# CONTROL_MODULE register map
Vendor: Texas Instruments
Registers are 32-bit, access per field, no defined reset value unless marked. A register's access mark holds for its fields unless they carry their own. Offsets are as the file gives them; [hi:lo] are bit positions; {n}, {i} and the like mark numbered series.

## CONTROL_MODULE (part 5 of 5)
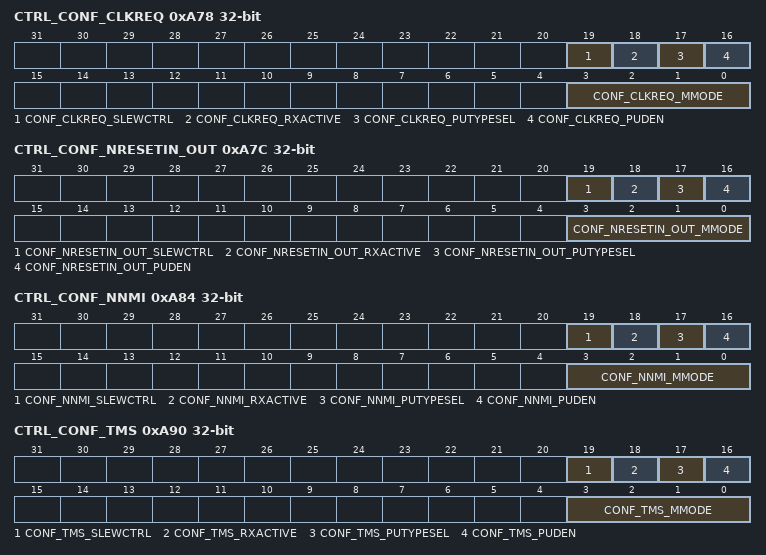
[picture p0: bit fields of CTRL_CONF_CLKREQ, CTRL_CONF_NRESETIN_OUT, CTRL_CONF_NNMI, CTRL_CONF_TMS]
0xA78 CTRL_CONF_CLKREQ
  [19] CONF_CLKREQ_SLEWCTRL rw — Select between Faster or Slower Slew rate [[br]]0 = fast [[br]]1 = slow
  [18] CONF_CLKREQ_RXACTIVE rw — Input Enable Value for the PAD [[br]]0 = receiver disabled [[br]]1 = receiver enabled
  [17] CONF_CLKREQ_PUTYPESEL rw — Pad Pullup / Pulldown Type Selection [[br]]0 = Pulldown selected [[br]]1 = Pullup selected
  [16] CONF_CLKREQ_PUDEN rw — Pad Pullup / Pulldown Enable. [[br]]This is an active low signal [[br]]1 = Pullup / Pulldown disabled [[br]]0 = Pullup / Pulldown enabled
  [3:0] CONF_CLKREQ_MMODE rw — Pad Functional Signal Mux Select
0xA7C CTRL_CONF_NRESETIN_OUT
  [19] CONF_NRESETIN_OUT_SLEWCTRL rw — Select between Faster or Slower Slew rate [[br]]0 = fast [[br]]1 = slow
  [18] CONF_NRESETIN_OUT_RXACTIVE rw — Input Enable Value for the PAD [[br]]0 = receiver disabled [[br]]1 = receiver enabled
  [17] CONF_NRESETIN_OUT_PUTYPESEL rw — Pad Pullup / Pulldown Type Selection [[br]]0 = Pulldown selected [[br]]1 = Pullup selected
  [16] CONF_NRESETIN_OUT_PUDEN rw — Pad Pullup / Pulldown Enable. [[br]]This is an active low signal [[br]]1 = Pullup / Pulldown disabled [[br]]0 = Pullup / Pulldown enabled
  [3:0] CONF_NRESETIN_OUT_MMODE rw — Pad Functional Signal Mux Select
0xA84 CTRL_CONF_NNMI
  [19] CONF_NNMI_SLEWCTRL rw — Select between Faster or Slower Slew rate [[br]]0 = fast [[br]]1 = slow
  [18] CONF_NNMI_RXACTIVE rw — Input Enable Value for the PAD [[br]]0 = receiver disabled [[br]]1 = receiver enabled
  [17] CONF_NNMI_PUTYPESEL rw — Pad Pullup / Pulldown Type Selection [[br]]0 = Pulldown selected [[br]]1 = Pullup selected
  [16] CONF_NNMI_PUDEN rw — Pad Pullup / Pulldown Enable. [[br]]This is an active low signal [[br]]1 = Pullup / Pulldown disabled [[br]]0 = Pullup / Pulldown enabled
  [3:0] CONF_NNMI_MMODE rw — Pad Functional Signal Mux Select
0xA90 CTRL_CONF_TMS
  [19] CONF_TMS_SLEWCTRL rw — Select between Faster or Slower Slew rate [[br]]0 = fast [[br]]1 = slow
  [18] CONF_TMS_RXACTIVE rw — Input Enable Value for the PAD [[br]]0 = receiver disabled [[br]]1 = receiver enabled
  [17] CONF_TMS_PUTYPESEL rw — Pad Pullup / Pulldown Type Selection [[br]]0 = Pulldown selected [[br]]1 = Pullup selected
  [16] CONF_TMS_PUDEN rw — Pad Pullup / Pulldown Enable. [[br]]This is an active low signal [[br]]1 = Pullup / Pulldown disabled [[br]]0 = Pullup / Pulldown enabled
  [3:0] CONF_TMS_MMODE rw — Pad Functional Signal Mux Select
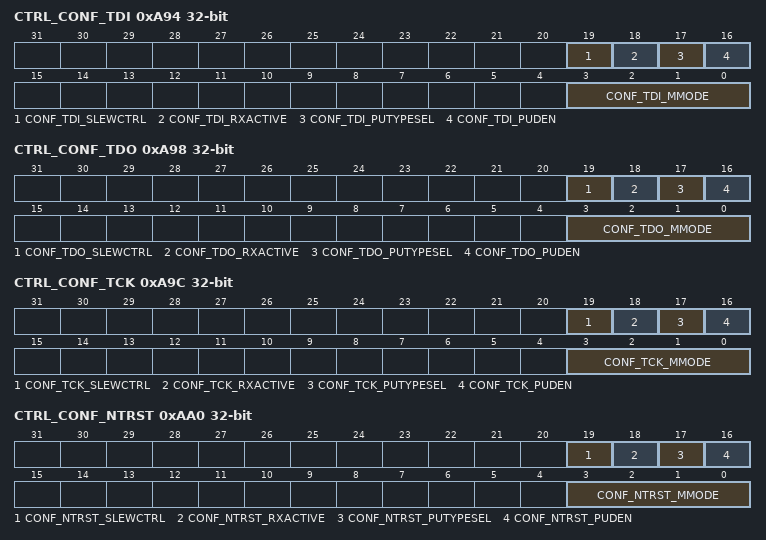
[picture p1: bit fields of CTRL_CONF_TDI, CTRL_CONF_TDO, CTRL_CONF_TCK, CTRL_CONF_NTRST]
0xA94 CTRL_CONF_TDI
  [19] CONF_TDI_SLEWCTRL rw — Select between Faster or Slower Slew rate [[br]]0 = fast [[br]]1 = slow
  [18] CONF_TDI_RXACTIVE rw — Input Enable Value for the PAD [[br]]0 = receiver disabled [[br]]1 = receiver enabled
  [17] CONF_TDI_PUTYPESEL rw — Pad Pullup / Pulldown Type Selection [[br]]0 = Pulldown selected [[br]]1 = Pullup selected
  [16] CONF_TDI_PUDEN rw — Pad Pullup / Pulldown Enable. [[br]]This is an active low signal [[br]]1 = Pullup / Pulldown disabled [[br]]0 = Pullup / Pulldown enabled
  [3:0] CONF_TDI_MMODE rw — Pad Functional Signal Mux Select
0xA98 CTRL_CONF_TDO
  [19] CONF_TDO_SLEWCTRL rw — Select between Faster or Slower Slew rate [[br]]0 = fast [[br]]1 = slow
  [18] CONF_TDO_RXACTIVE rw — Input Enable Value for the PAD [[br]]0 = receiver disabled [[br]]1 = receiver enabled
  [17] CONF_TDO_PUTYPESEL rw — Pad Pullup / Pulldown Type Selection [[br]]0 = Pulldown selected [[br]]1 = Pullup selected
  [16] CONF_TDO_PUDEN rw — Pad Pullup / Pulldown Enable. [[br]]This is an active low signal [[br]]1 = Pullup / Pulldown disabled [[br]]0 = Pullup / Pulldown enabled
  [3:0] CONF_TDO_MMODE rw — Pad Functional Signal Mux Select
0xA9C CTRL_CONF_TCK
  [19] CONF_TCK_SLEWCTRL rw — Select between Faster or Slower Slew rate [[br]]0 = fast [[br]]1 = slow
  [18] CONF_TCK_RXACTIVE rw — Input Enable Value for the PAD [[br]]0 = receiver disabled [[br]]1 = receiver enabled
  [17] CONF_TCK_PUTYPESEL rw — Pad Pullup / Pulldown Type Selection [[br]]0 = Pulldown selected [[br]]1 = Pullup selected
  [16] CONF_TCK_PUDEN rw — Pad Pullup / Pulldown Enable. [[br]]This is an active low signal [[br]]1 = Pullup / Pulldown disabled [[br]]0 = Pullup / Pulldown enabled
  [3:0] CONF_TCK_MMODE rw — Pad Functional Signal Mux Select
0xAA0 CTRL_CONF_NTRST
  [19] CONF_NTRST_SLEWCTRL rw — Select between Faster or Slower Slew rate [[br]]0 = fast [[br]]1 = slow
  [18] CONF_NTRST_RXACTIVE rw — Input Enable Value for the PAD [[br]]0 = receiver disabled [[br]]1 = receiver enabled
  [17] CONF_NTRST_PUTYPESEL rw — Pad Pullup / Pulldown Type Selection [[br]]0 = Pulldown selected [[br]]1 = Pullup selected
  [16] CONF_NTRST_PUDEN rw — Pad Pullup / Pulldown Enable. [[br]]This is an active low signal [[br]]1 = Pullup / Pulldown disabled [[br]]0 = Pullup / Pulldown enabled
  [3:0] CONF_NTRST_MMODE rw — Pad Functional Signal Mux Select
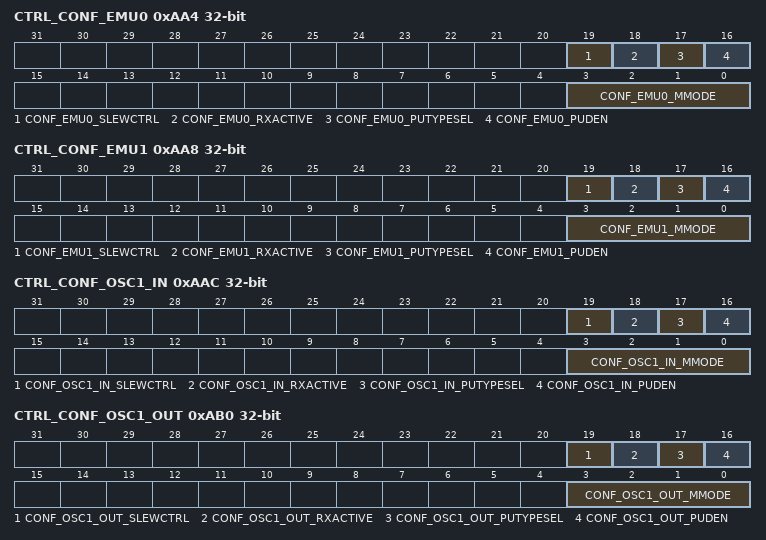
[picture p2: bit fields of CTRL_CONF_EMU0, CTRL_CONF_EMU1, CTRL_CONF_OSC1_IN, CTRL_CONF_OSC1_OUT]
0xAA4 CTRL_CONF_EMU0
  [19] CONF_EMU0_SLEWCTRL rw — Select between Faster or Slower Slew rate [[br]]0 = fast [[br]]1 = slow
  [18] CONF_EMU0_RXACTIVE rw — Input Enable Value for the PAD [[br]]0 = receiver disabled [[br]]1 = receiver enabled
  [17] CONF_EMU0_PUTYPESEL rw — Pad Pullup / Pulldown Type Selection [[br]]0 = Pulldown selected [[br]]1 = Pullup selected
  [16] CONF_EMU0_PUDEN rw — Pad Pullup / Pulldown Enable. [[br]]This is an active low signal [[br]]1 = Pullup / Pulldown disabled [[br]]0 = Pullup / Pulldown enabled
  [3:0] CONF_EMU0_MMODE rw — Pad Functional Signal Mux Select
0xAA8 CTRL_CONF_EMU1
  [19] CONF_EMU1_SLEWCTRL rw — Select between Faster or Slower Slew rate [[br]]0 = fast [[br]]1 = slow
  [18] CONF_EMU1_RXACTIVE rw — Input Enable Value for the PAD [[br]]0 = receiver disabled [[br]]1 = receiver enabled
  [17] CONF_EMU1_PUTYPESEL rw — Pad Pullup / Pulldown Type Selection [[br]]0 = Pulldown selected [[br]]1 = Pullup selected
  [16] CONF_EMU1_PUDEN rw — Pad Pullup / Pulldown Enable. [[br]]This is an active low signal [[br]]1 = Pullup / Pulldown disabled [[br]]0 = Pullup / Pulldown enabled
  [3:0] CONF_EMU1_MMODE rw — Pad Functional Signal Mux Select
0xAAC CTRL_CONF_OSC1_IN
  [19] CONF_OSC1_IN_SLEWCTRL rw — Select between Faster or Slower Slew rate [[br]]0 = fast [[br]]1 = slow
  [18] CONF_OSC1_IN_RXACTIVE rw — Input Enable Value for the PAD [[br]]0 = receiver disabled [[br]]1 = receiver enabled
  [17] CONF_OSC1_IN_PUTYPESEL rw — Pad Pullup / Pulldown Type Selection [[br]]0 = Pulldown selected [[br]]1 = Pullup selected
  [16] CONF_OSC1_IN_PUDEN rw — Pad Pullup / Pulldown Enable. [[br]]This is an active low signal [[br]]1 = Pullup / Pulldown disabled [[br]]0 = Pullup / Pulldown enabled
  [3:0] CONF_OSC1_IN_MMODE rw — Pad Functional Signal Mux Select
0xAB0 CTRL_CONF_OSC1_OUT
  [19] CONF_OSC1_OUT_SLEWCTRL rw — Select between Faster or Slower Slew rate [[br]]0 = fast [[br]]1 = slow
  [18] CONF_OSC1_OUT_RXACTIVE rw — Input Enable Value for the PAD [[br]]0 = receiver disabled [[br]]1 = receiver enabled
  [17] CONF_OSC1_OUT_PUTYPESEL rw — Pad Pullup / Pulldown Type Selection [[br]]0 = Pulldown selected [[br]]1 = Pullup selected
  [16] CONF_OSC1_OUT_PUDEN rw — Pad Pullup / Pulldown Enable. [[br]]This is an active low signal [[br]]1 = Pullup / Pulldown disabled [[br]]0 = Pullup / Pulldown enabled
  [3:0] CONF_OSC1_OUT_MMODE rw — Pad Functional Signal Mux Select
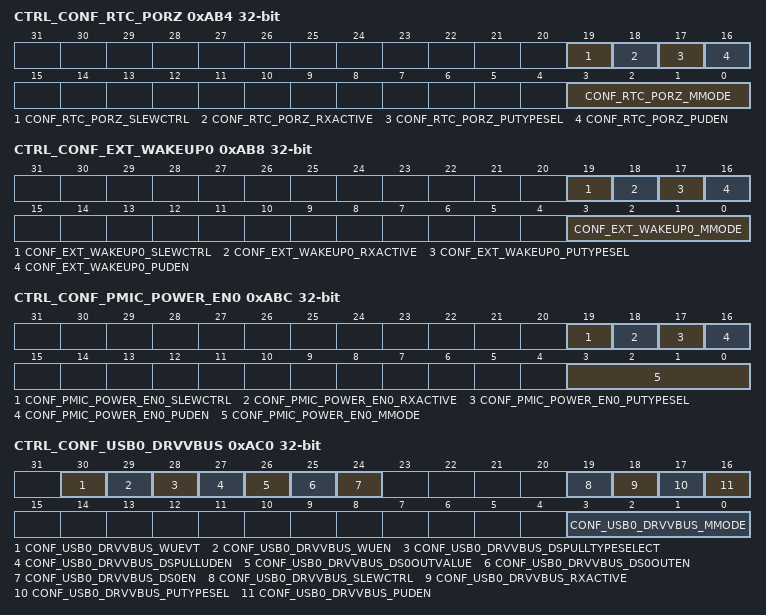
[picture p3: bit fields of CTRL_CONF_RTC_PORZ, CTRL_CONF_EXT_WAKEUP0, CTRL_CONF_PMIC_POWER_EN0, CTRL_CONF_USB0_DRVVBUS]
0xAB4 CTRL_CONF_RTC_PORZ
  [19] CONF_RTC_PORZ_SLEWCTRL rw — Select between Faster or Slower Slew rate [[br]]0 = fast [[br]]1 = slow
  [18] CONF_RTC_PORZ_RXACTIVE rw — Input Enable Value for the PAD [[br]]0 = receiver disabled [[br]]1 = receiver enabled
  [17] CONF_RTC_PORZ_PUTYPESEL rw — Pad Pullup / Pulldown Type Selection [[br]]0 = Pulldown selected [[br]]1 = Pullup selected
  [16] CONF_RTC_PORZ_PUDEN rw — Pad Pullup / Pulldown Enable. [[br]]This is an active low signal [[br]]1 = Pullup / Pulldown disabled [[br]]0 = Pullup / Pulldown enabled
  [3:0] CONF_RTC_PORZ_MMODE rw — Pad Functional Signal Mux Select
0xAB8 CTRL_CONF_EXT_WAKEUP0
  [19] CONF_EXT_WAKEUP0_SLEWCTRL rw — Select between Faster or Slower Slew rate [[br]]0 = fast [[br]]1 = slow
  [18] CONF_EXT_WAKEUP0_RXACTIVE rw — Input Enable Value for the PAD [[br]]0 = receiver disabled [[br]]1 = receiver enabled
  [17] CONF_EXT_WAKEUP0_PUTYPESEL rw — Pad Pullup / Pulldown Type Selection [[br]]0 = Pulldown selected [[br]]1 = Pullup selected
  [16] CONF_EXT_WAKEUP0_PUDEN rw — Pad Pullup / Pulldown Enable. [[br]]This is an active low signal [[br]]1 = Pullup / Pulldown disabled [[br]]0 = Pullup / Pulldown enabled
  [3:0] CONF_EXT_WAKEUP0_MMODE rw — Pad Functional Signal Mux Select
0xABC CTRL_CONF_PMIC_POWER_EN0
  [19] CONF_PMIC_POWER_EN0_SLEWCTRL rw — Select between Faster or Slower Slew rate [[br]]0 = fast [[br]]1 = slow
  [18] CONF_PMIC_POWER_EN0_RXACTIVE rw — Input Enable Value for the PAD [[br]]0 = receiver disabled [[br]]1 = receiver enabled
  [17] CONF_PMIC_POWER_EN0_PUTYPESEL rw — Pad Pullup / Pulldown Type Selection [[br]]0 = Pulldown selected [[br]]1 = Pullup selected
  [16] CONF_PMIC_POWER_EN0_PUDEN rw — Pad Pullup / Pulldown Enable. [[br]]This is an active low signal [[br]]1 = Pullup / Pulldown disabled [[br]]0 = Pullup / Pulldown enabled
  [3:0] CONF_PMIC_POWER_EN0_MMODE rw — Pad Functional Signal Mux Select
0xAC0 CTRL_CONF_USB0_DRVVBUS
  [30] CONF_USB0_DRVVBUS_WUEVT ro — Wakeup Event [[br]]0 = No event [[br]]1 = Event occurred
  [29] CONF_USB0_DRVVBUS_WUEN rw — Wakeup enable [[br]]0 = disable [[br]]1 = enable
  [28] CONF_USB0_DRVVBUS_DSPULLTYPESELECT rw — DS0 mode Pull-Up/Down selection [[br]]0 = Offmode Pull-Down selected [[br]]1 = Offmode Pull-Up selected
  [27] CONF_USB0_DRVVBUS_DSPULLUDEN rw — DS0 mode Pull-Up/Down enable. [[br]]This is an active low signal. [[br]]1 = Pullup / Pulldown disabled [[br]]0 = Pullup / Pulldown enabled
  [26] CONF_USB0_DRVVBUS_DS0OUTVALUE rw — DS0 mode output value [[br]]0 = Set value at 0 [[br]]1 = Set value at 1
  [25] CONF_USB0_DRVVBUS_DS0OUTEN rw — DS0 mode output enable This is an active low signal [[br]]0 = Output Enable [[br]]1 = Output Disable
  [24] CONF_USB0_DRVVBUS_DS0EN rw — DS0 mode override control [[br]]0: IO state keeps its previous state when DS0 mode is active [[br]]1: IO state is forced to OFF mode value when DS0 mode is active
  [19] CONF_USB0_DRVVBUS_SLEWCTRL rw — Select between Faster or Slower Slew rate [[br]]0 = fast [[br]]1 = slow
  [18] CONF_USB0_DRVVBUS_RXACTIVE rw — Input Enable Value for the PAD [[br]]0 = receiver disabled [[br]]1 = receiver enabled
  [17] CONF_USB0_DRVVBUS_PUTYPESEL rw — Pad Pullup / Pulldown Type Selection [[br]]0 = Pulldown selected [[br]]1 = Pullup selected
  [16] CONF_USB0_DRVVBUS_PUDEN rw — Pad Pullup / Pulldown Enable. [[br]]This is an active low signal [[br]]1 = Pullup / Pulldown disabled [[br]]0 = Pullup / Pulldown enabled
  [3:0] CONF_USB0_DRVVBUS_MMODE rw — Pad Functional Signal Mux Select
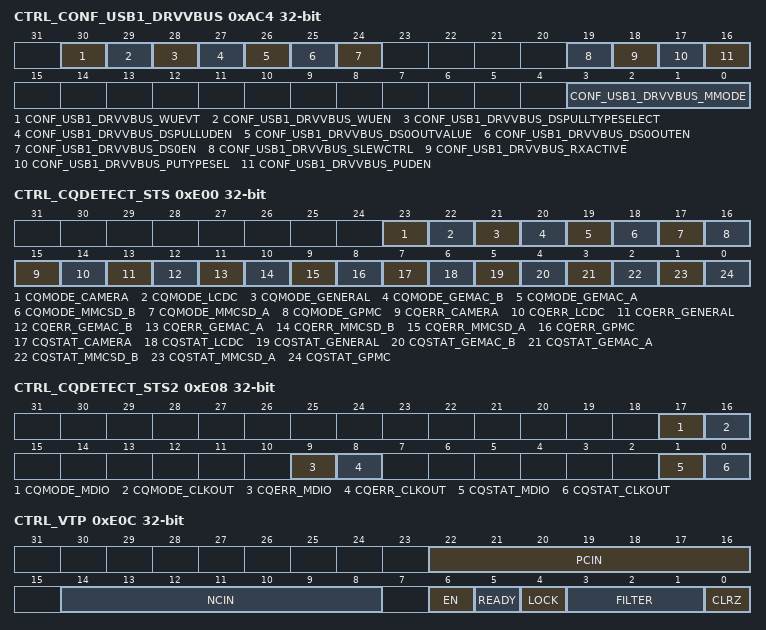
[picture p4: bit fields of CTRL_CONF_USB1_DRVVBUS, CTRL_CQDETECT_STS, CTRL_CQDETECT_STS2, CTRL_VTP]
0xAC4 CTRL_CONF_USB1_DRVVBUS
  [30] CONF_USB1_DRVVBUS_WUEVT ro — Wakeup Event [[br]]0 = No event [[br]]1 = Event occurred
  [29] CONF_USB1_DRVVBUS_WUEN rw — Wakeup enable [[br]]0 = disable [[br]]1 = enable
  [28] CONF_USB1_DRVVBUS_DSPULLTYPESELECT rw — DS0 mode Pull-Up/Down selection [[br]]0 = Offmode Pull-Down selected [[br]]1 = Offmode Pull-Up selected
  [27] CONF_USB1_DRVVBUS_DSPULLUDEN rw — DS0 mode Pull-Up/Down enable. [[br]]This is an active low signal. [[br]]1 = Pullup / Pulldown disabled [[br]]0 = Pullup / Pulldown enabled
  [26] CONF_USB1_DRVVBUS_DS0OUTVALUE rw — DS0 mode output value [[br]]0 = Set value at 0 [[br]]1 = Set value at 1
  [25] CONF_USB1_DRVVBUS_DS0OUTEN rw — DS0 mode output enable This is an active low signal [[br]]0 = Output Enable [[br]]1 = Output Disable
  [24] CONF_USB1_DRVVBUS_DS0EN rw — DS0 mode override control [[br]]0: IO state keeps its previous state when DS0 mode is active [[br]]1: IO state is forced to OFF mode value when DS0 mode is active
  [19] CONF_USB1_DRVVBUS_SLEWCTRL rw — Select between Faster or Slower Slew rate [[br]]0 = fast [[br]]1 = slow
  [18] CONF_USB1_DRVVBUS_RXACTIVE rw — Input Enable Value for the PAD [[br]]0 = receiver disabled [[br]]1 = receiver enabled
  [17] CONF_USB1_DRVVBUS_PUTYPESEL rw — Pad Pullup / Pulldown Type Selection [[br]]0 = Pulldown selected [[br]]1 = Pullup selected
  [16] CONF_USB1_DRVVBUS_PUDEN rw — Pad Pullup / Pulldown Enable. [[br]]This is an active low signal [[br]]1 = Pullup / Pulldown disabled [[br]]0 = Pullup / Pulldown enabled
  [3:0] CONF_USB1_DRVVBUS_MMODE rw — Pad Functional Signal Mux Select
0xE00 CTRL_CQDETECT_STS
  [23] CQMODE_CAMERA rw — [[br]]0 : Set IO to 1.8V [[br]]1 : Set IO to 3.3V
  [22] CQMODE_LCDC rw — [[br]]0 : Set IO to 1.8V [[br]]1 : Set IO to 3.3V
  [21] CQMODE_GENERAL rw — [[br]]0 : Set IO to 1.8V [[br]]1 : Set IO to 3.3V
  [20] CQMODE_GEMAC_B rw — [[br]]0 : Set IO to 1.8V [[br]]1 : Set IO to 3.3V
  [19] CQMODE_GEMAC_A rw — [[br]]0 : Set IO to 1.8V [[br]]1 : Set IO to 3.3V
  [18] CQMODE_MMCSD_B rw — [[br]]0 : Set IO to 1.8V [[br]]1 : Set IO to 3.3V
  [17] CQMODE_MMCSD_A rw — [[br]]0 : Set IO to 1.8V [[br]]1 : Set IO to 3.3V
  [16] CQMODE_GPMC rw — [[br]]0 : Set IO to 1.8V [[br]]1 : Set IO to 3.3V
  [15] CQERR_CAMERA ro — CQDetect Mode Error Status
  [14] CQERR_LCDC ro — CQDetect Mode Error Status
  [13] CQERR_GENERAL ro — CQDetect Mode Error Status
  [12] CQERR_GEMAC_B ro — CQDetect Mode Error Status
  [11] CQERR_GEMAC_A ro — CQDetect Mode Error Status
  [10] CQERR_MMCSD_B ro — CQDetect Mode Error Status
  [9] CQERR_MMCSD_A ro — CQDetect Mode Error Status
  [8] CQERR_GPMC ro — CQDetect Mode Error Status
  [7] CQSTAT_CAMERA ro — [[br]]1 : IOs are 3.3V mode [[br]]0 : IOs are 1.8V mode
  [6] CQSTAT_LCDC ro — [[br]]1 : IOs are 3.3V mode [[br]]0 : IOs are 1.8V mode
  [5] CQSTAT_GENERAL ro — [[br]]1 : IOs are 3.3V mode [[br]]0 : IOs are 1.8V mode
  [4] CQSTAT_GEMAC_B ro — [[br]]1 : IOs are 3.3V mode [[br]]0 : IOs are 1.8V mode
  [3] CQSTAT_GEMAC_A ro — [[br]]1 : IOs are 3.3V mode [[br]]0 : IOs are 1.8V mode
  [2] CQSTAT_MMCSD_B ro — [[br]]1 : IOs are 3.3V mode [[br]]0 : IOs are 1.8V mode
  [1] CQSTAT_MMCSD_A ro — [[br]]1 : IOs are 3.3V mode [[br]]0 : IOs are 1.8V mode
  [0] CQSTAT_GPMC ro — [[br]]1 : IOs are 3.3V mode [[br]]0 : IOs are 1.8V mode
0xE04 CTRL_DDR_IO
  [31] DDR3_RST_DEF_VAL rw — [[br]]0 = DDR3 RESET controlled via controller/PHY [[br]]1 = DDR RESET is overridden to value HIGH[[br]]As part of boot initialization (and before DDR/EMIF init) this bit must be written to value zero.
0xE08 CTRL_CQDETECT_STS2
  [17] CQMODE_MDIO rw — [[br]]0 : Set IO to 1.8V [[br]]1 : Set IO to 3.3V
  [16] CQMODE_CLKOUT rw — [[br]]0 : Set IO to 1.8V [[br]]1 : Set IO to 3.3V
  [9] CQERR_MDIO ro — CQDetect Mode Error Status
  [8] CQERR_CLKOUT ro — CQDetect Mode Error Status
  [1] CQSTAT_MDIO ro — [[br]]1 : IOs are 3.3V mode [[br]]0 : IOs are 1.8V mode
  [0] CQSTAT_CLKOUT ro — [[br]]1 : IOs are 3.3V mode [[br]]0 : IOs are 1.8V mode
0xE0C CTRL_VTP
  [22:16] PCIN rw — Default/reset values of 'P' for the VTP controller.
  [14:8] NCIN rw — Default/reset values of 'N' for the VTP controller.
  [6] EN rw — active high enable
  [5] READY ro — [[br]]0: Training sequence is not complete. [[br]]1: Training sequence is complete.
  [4] LOCK rw — [[br]]0: Normal operation dynamic update [[br]]1: freeze dynamic update pwrdn controller
  [3:1] FILTER rw — Digital filter bits
  [0] CLRZ rw — clears flops start count again after low going pulse
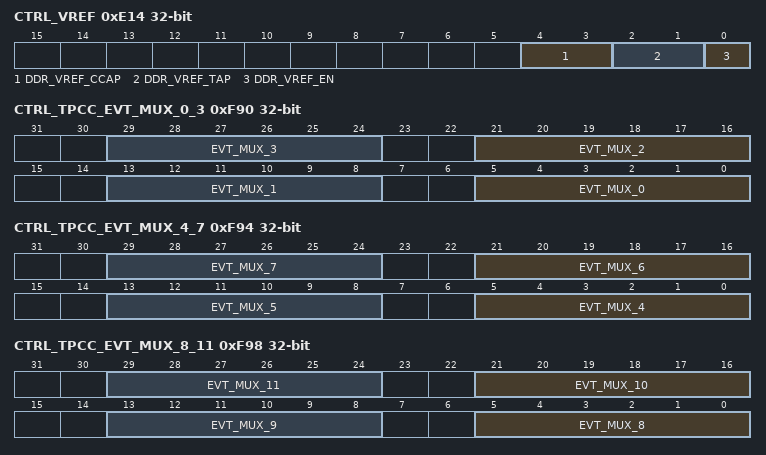
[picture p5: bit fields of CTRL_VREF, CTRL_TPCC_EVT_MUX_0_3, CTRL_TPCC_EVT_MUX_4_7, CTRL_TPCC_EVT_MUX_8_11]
0xE14 CTRL_VREF
  [4:3] DDR_VREF_CCAP rw — select for coupling cap for DDR [[br]]00 : No capacitor connected[[br]]01 : Capacitor between BIAS2 and VSS[[br]]10 : Capacitor between BIAS2 and VDDS[[br]]11: Capacitor between BIAS2 and VSS and Capacitor between BIAS2 and VDDS
  [2:1] DDR_VREF_TAP rw — select for int ref for DDR [[br]]00 : Pad/Bias2 connected to internal reference VDDS/2 for 2uA current load[[br]]01 : Pad/Bias2 connected to internal reference VDDS/2 for 4uA current load[[br]]10 : Pad/Bias2 connected to internal reference VDDS/2 for 6uA current load[[br]]11 : Pad/Bias2 connected to internal reference VDDS/2 for 8uA current load
  [0] DDR_VREF_EN rw — active high internal reference enable for DDR
0xF90 CTRL_TPCC_EVT_MUX_0_3
  [8n+5:8n] EVT_MUX_{n} rw (n=0..3) — Selects 1 of 64 inputs for DMA event {n}
0xF94 CTRL_TPCC_EVT_MUX_4_7
  [8n-27:8n-32] EVT_MUX_{n} rw (n=4..7) — Selects 1 of 64 inputs for DMA event {n}
0xF98 CTRL_TPCC_EVT_MUX_8_11
  [8n-59:8n-64] EVT_MUX_{n} rw (n=8..11) — Selects 1 of 64 inputs for DMA event {n}
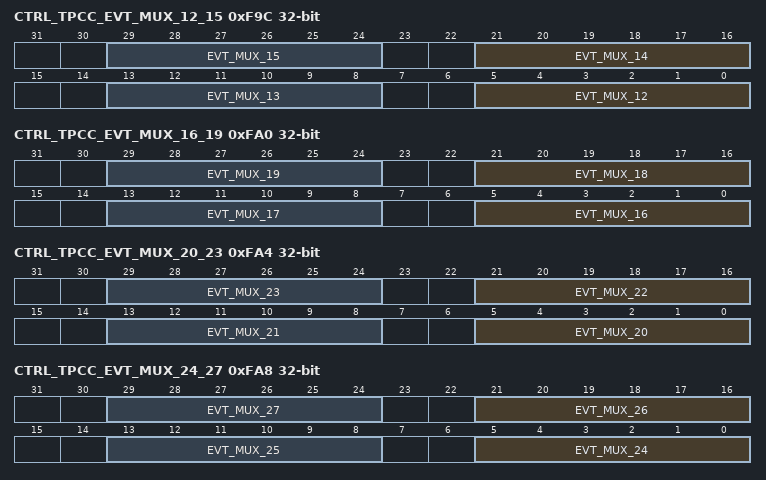
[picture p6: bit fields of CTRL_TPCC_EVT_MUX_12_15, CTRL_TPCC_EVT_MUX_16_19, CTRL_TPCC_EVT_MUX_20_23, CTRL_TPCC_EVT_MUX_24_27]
0xF9C CTRL_TPCC_EVT_MUX_12_15
  [8n-91:8n-96] EVT_MUX_{n} rw (n=12..15) — Selects 1 of 64 inputs for DMA event {n}
0xFA0 CTRL_TPCC_EVT_MUX_16_19
  [8n-123:8n-128] EVT_MUX_{n} rw (n=16..19) — Selects 1 of 64 inputs for DMA event {n}
0xFA4 CTRL_TPCC_EVT_MUX_20_23
  [8n-155:8n-160] EVT_MUX_{n} rw (n=20..23) — Selects 1 of 64 inputs for DMA event {n}
0xFA8 CTRL_TPCC_EVT_MUX_24_27
  [8n-187:8n-192] EVT_MUX_{n} rw (n=24..27) — Selects 1 of 64 inputs for DMA event {n}
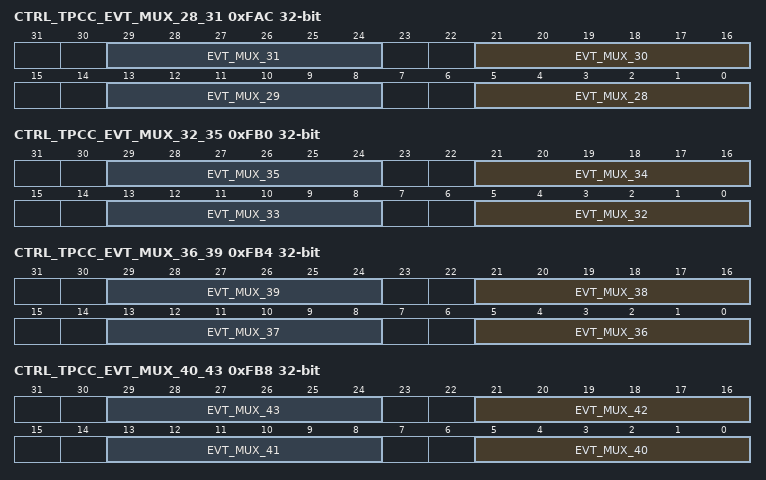
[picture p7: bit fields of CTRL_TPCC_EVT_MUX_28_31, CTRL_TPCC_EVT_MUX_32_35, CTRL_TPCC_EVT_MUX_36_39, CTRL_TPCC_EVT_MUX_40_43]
0xFAC CTRL_TPCC_EVT_MUX_28_31
  [8n-219:8n-224] EVT_MUX_{n} rw (n=28..31) — Selects 1 of 64 inputs for DMA event {n}
0xFB0 CTRL_TPCC_EVT_MUX_32_35
  [8n-251:8n-256] EVT_MUX_{n} rw (n=32..35) — Selects 1 of 64 inputs for DMA event {n}
0xFB4 CTRL_TPCC_EVT_MUX_36_39
  [8n-283:8n-288] EVT_MUX_{n} rw (n=36..39) — Selects 1 of 64 inputs for DMA event {n}
0xFB8 CTRL_TPCC_EVT_MUX_40_43
  [8n-315:8n-320] EVT_MUX_{n} rw (n=40..43) — Selects 1 of 64 inputs for DMA event {n}
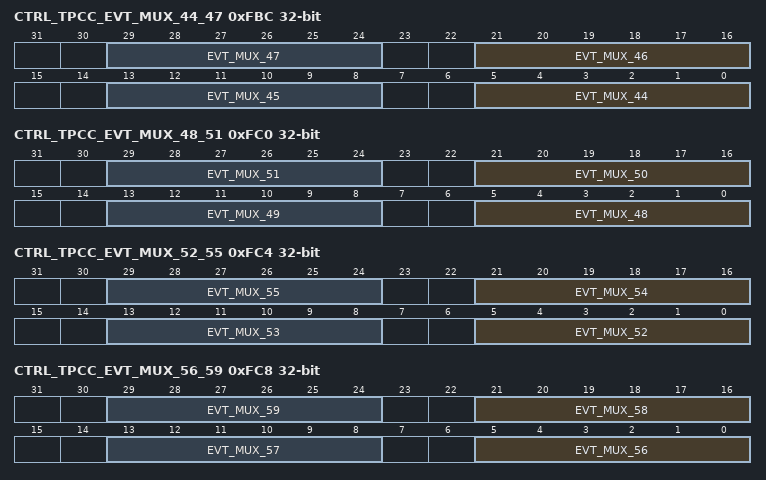
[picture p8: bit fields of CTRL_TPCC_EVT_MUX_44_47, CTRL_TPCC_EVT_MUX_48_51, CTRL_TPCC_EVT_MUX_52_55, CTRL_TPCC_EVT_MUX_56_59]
0xFBC CTRL_TPCC_EVT_MUX_44_47
  [8n-347:8n-352] EVT_MUX_{n} rw (n=44..47) — Selects 1 of 64 inputs for DMA event {n}
0xFC0 CTRL_TPCC_EVT_MUX_48_51
  [8n-379:8n-384] EVT_MUX_{n} rw (n=48..51) — Selects 1 of 64 inputs for DMA event {n}
0xFC4 CTRL_TPCC_EVT_MUX_52_55
  [8n-411:8n-416] EVT_MUX_{n} rw (n=52..55) — Selects 1 of 64 inputs for DMA event {n}
0xFC8 CTRL_TPCC_EVT_MUX_56_59
  [8n-443:8n-448] EVT_MUX_{n} rw (n=56..59) — Selects 1 of 64 inputs for DMA event {n}
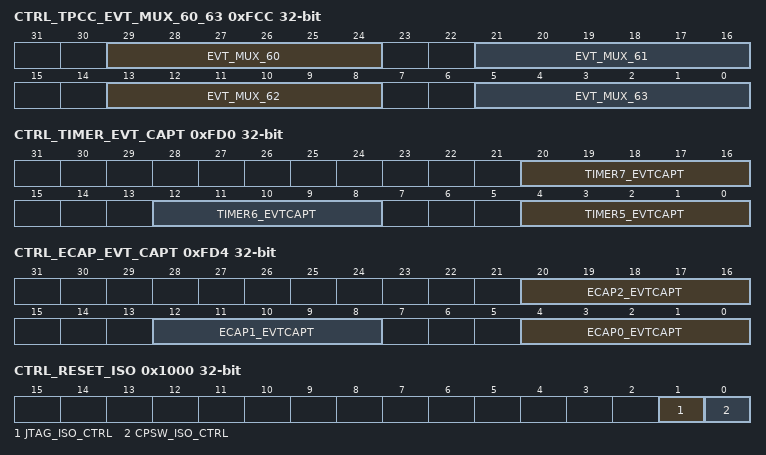
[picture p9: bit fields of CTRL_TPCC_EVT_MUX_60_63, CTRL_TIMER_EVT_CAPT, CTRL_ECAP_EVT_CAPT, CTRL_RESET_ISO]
0xFCC CTRL_TPCC_EVT_MUX_60_63
  [29:24] EVT_MUX_60 rw — Selects 1 of 64 inputs for DMA event 63
  [21:16] EVT_MUX_61 rw — Selects 1 of 64 inputs for DMA event 62
  [13:8] EVT_MUX_62 rw — Selects 1 of 64 inputs for DMA event 61
  [5:0] EVT_MUX_63 rw — Selects 1 of 64 inputs for DMA event 60
0xFD0 CTRL_TIMER_EVT_CAPT
  [20:16] TIMER7_EVTCAPT rw — Timer 7 event capture mux
  [12:8] TIMER6_EVTCAPT rw — Timer 6 event capture mux
  [4:0] TIMER5_EVTCAPT rw — Timer 5 event capture mux
0xFD4 CTRL_ECAP_EVT_CAPT
  [20:16] ECAP2_EVTCAPT rw — ECAP2 event capture mux
  [12:8] ECAP1_EVTCAPT rw — ECAP1 event capture mux
  [4:0] ECAP0_EVTCAPT rw — ECAP0 event capture mux
0xFD8 CTRL_ADC0_EVT_CAPT
  [3:0] ADC0_EVTCAPT rw — ADC0 event capture mux
0xFDC CTRL_ADC1_EVT_CAPT
  [3:0] ADC1_EVTCAPT rw — ADC1 event capture mux
0x1000 CTRL_RESET_ISO
  [1] JTAG_ISO_CTRL rw — [[br]]0 : JTAG IOs are not isolated from warm reset [[br]]1 : JTAG IOs are isolated from warm reset
  [0] CPSW_ISO_CTRL rw — [[br]]0 : Ethernet Switch is not isolated from warm reset [[br]]1 : Ethernet Switch is isolated from warm reset[[br]]Please refer to Ethernet Switch reset isolation microarch for details on which registers are isolated in the SOC.
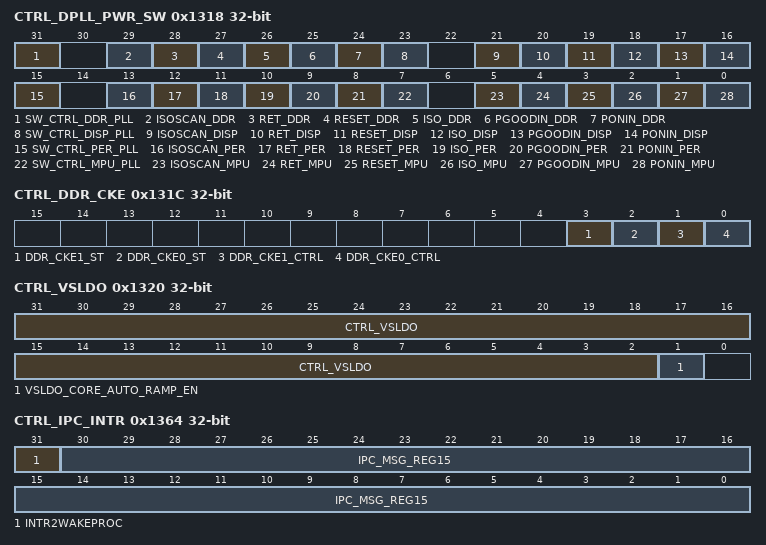
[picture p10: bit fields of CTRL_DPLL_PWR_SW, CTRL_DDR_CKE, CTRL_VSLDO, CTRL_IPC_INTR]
0x1318 CTRL_DPLL_PWR_SW
  [31] SW_CTRL_DDR_PLL rw — Enable software control over DDR DPLL RET RESET ISO PGOODIN PONIN for power savings. [[br]]0: PRCM controls the DPLL reset RET = 0 ISO = 0 PGOODIN = 1 PONIN = 1. [[br]]1: Controlled by corresponding bits in this register.
  [29] ISOSCAN_DDR rw — Drives ISOSCAN of DDR PLL
  [28] RET_DDR rw — Drives RET signal of DDR PLL
  [27] RESET_DDR rw — Drives RESET of DDR DPLL
  [26] ISO_DDR rw — Drives ISO of DDR DPLL
  [25] PGOODIN_DDR rw — Drives PGOODIN of DDR DPLL
  [24] PONIN_DDR rw — Drives PONIN of DDR DPLL
  [23] SW_CTRL_DISP_PLL rw — Enable software control over DISP DPLL RET RESET ISO PGOODIN PONIN for power savings. [[br]]0: PRCM controls the DPLL reset RET = 0 ISO = 0 PGOODIN = 1 PONIN = 1. [[br]]1: Controlled by corresponding bits in this register.
  [21] ISOSCAN_DISP rw — Drives ISOSCAN of DISP PLL
  [20] RET_DISP rw — Drives RET of DISP DPLL
  [19] RESET_DISP rw — Drives RESET of DISP DPLL
  [18] ISO_DISP rw — Drives ISO of DISP DPLL
  [17] PGOODIN_DISP rw — Drives PGOODIN of DISP DPLL
  [16] PONIN_DISP rw — Drives PONIN of DISP DPLL
  [15] SW_CTRL_PER_PLL rw — Enable software control over PER DPLL RET RESET ISO PGOODIN PONIN for power savings. [[br]]0: PRCM controls the DPLL reset RET = 0 ISO = 0 PGOODIN = 1 PONIN = 1. [[br]]1: Controlled by corresponding bits in this register.
  [13] ISOSCAN_PER rw — Drives ISOSCAN of PER PLL
  [12] RET_PER rw — Drives RET of PER DPLL
  [11] RESET_PER rw — Drives RESET signal of PER DPLL
  [10] ISO_PER rw — Drives ISO signal of PER DPLL
  [9] PGOODIN_PER rw — Drives PGOODIN signal of PER DPLL
  [8] PONIN_PER rw — Drives PONIN signal of PER DPLL
  [7] SW_CTRL_MPU_PLL rw — Enable S/W control over MPU DPLL RET RESET ISO PGOODIN PONIN for power savings. [[br]]0: PRCM controls the DPLL reset RET = 0 ISO = 0 PGOODIN = 1 PONIN = 1. [[br]]1: Controlled by corresponding bits in this register.
  [5] ISOSCAN_MPU rw — Drives ISOSCAN of MPU PLL
  [4] RET_MPU rw — Drives RET of MPU DPLL
  [3] RESET_MPU rw — Drives RESET signal of MPU DPLL
  [2] ISO_MPU rw — Drives ISO signal of MPU DPLL
  [1] PGOODIN_MPU rw — Drives PGOODIN signal of MPU DPLL
  [0] PONIN_MPU rw — Drives PONIN signal of MPU DPLL
0x131C CTRL_DDR_CKE
  [3] DDR_CKE1_ST ro — CKE status bit
  [2] DDR_CKE0_ST ro — CKE status bit
  [1] DDR_CKE1_CTRL rw — CKE from EMIF/DDRPHY is ANDed with this bit. [[br]]0: CKE to memories gated off to zero. [[br]]External DRAM memories will not be able to register DDR commands from the controller. [[br]]1: Normal operation. [[br]]CKE is now controlled by EMIF/DDR PHY.
  [0] DDR_CKE0_CTRL rw — CKE from EMIF/DDRPHY is ANDed with this bit. [[br]]0: CKE to memories gated off to zero. [[br]]External DRAM memories will not be able to register DDR commands from this device. [[br]]1: Normal operation. [[br]]CKE is now controlled by EMIF/DDR PHY.
0x1320 CTRL_VSLDO
  [31:2] CTRL_VSLDO rw — Selectively Modifiable Attribute Bits (Spare Register)
  [1] VSLDO_CORE_AUTO_RAMP_EN rw — [[br]]0 : PRCM controls VSLDO [[br]]1 : Allows H/W to bring VSLDO out of retention on wakeup from deep-sleep
0x1324 CTRL_WAKEPROC_TXEV_EOI
  [0] CTRL_WAKEPROC_TXEV_EOI rw — TXEV (Event) from Wakeup processor is a pulse signal connected as interrupt to MPUSS IRQ(78) Since MPUSS expects level signals. [[br]]The TXEV pulse from WAKEPROC is converted to a level in glue logic. [[br]]The logic works as follows: On a 0-1 transition on TXEV, the IRQ[78] is set. For clearing the interrupt, S/W must do the following: 1) S/W must clear the IRQ[78] by writing a '1' to WAKEPROC_TXEV_EOI bit in this register, 2) This bit is sticky and for re-arming the IRQ[78], S/W must write a '0' to this field in the ISR.
{0x1328+4i} CTRL_IPC_MSG_REG{i} rw (i=0..14)
  [31:0] IPC_MSG_REG{i} — Inter Processor Messaging Register
0x1364 CTRL_IPC_INTR rw
  [31] INTR2WAKEPROC — Interrupt to M3
  [30:0] IPC_MSG_REG15 — Inter Processor Messaging Register
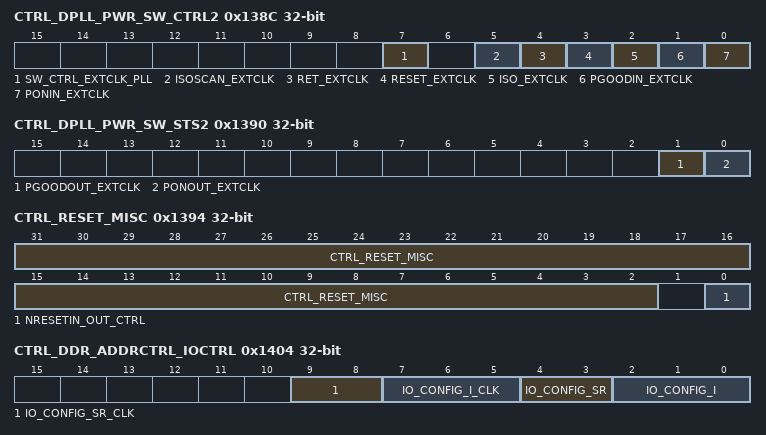
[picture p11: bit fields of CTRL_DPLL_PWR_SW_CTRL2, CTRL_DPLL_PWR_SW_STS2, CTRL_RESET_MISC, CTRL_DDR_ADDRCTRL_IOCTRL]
0x138C CTRL_DPLL_PWR_SW_CTRL2
  [7] SW_CTRL_EXTCLK_PLL rw — Enable S/W control over EXTCLK DPLL RET RESET ISO PGOODIN PONIN for power savings. [[br]]0: PRCM controls the DPLL reset RET = 0 ISO = 0 GOODIN = 1 PONIN = 1. [[br]]1: Controlled by corresponding bits in this register.
  [5] ISOSCAN_EXTCLK rw — Drives ISOSCAN of EXTCLK PLL
  [4] RET_EXTCLK rw — Drives RET of EXTCLK DPLL
  [3] RESET_EXTCLK rw — Drives RESET signal of EXTCLK DPLL
  [2] ISO_EXTCLK rw — Drives ISO signal of EXTCLK DPLL
  [1] PGOODIN_EXTCLK rw — Drives PGOODIN signal of EXTCLK DPLL
  [0] PONIN_EXTCLK rw — Drives PONIN signal of EXTCLK DPLL
0x1390 CTRL_DPLL_PWR_SW_STS2 ro
  [1] PGOODOUT_EXTCLK — PGOODOUT signal from EXTCLK DPLL
  [0] PONOUT_EXTCLK — PONOUT signal from EXTCLK DPLL
0x1394 CTRL_RESET_MISC
  [31:2] CTRL_RESET_MISC rw — Selectively Modifiable Attribute Bits (Spare Register)
  [0] NRESETIN_OUT_CTRL rw — When 0 nRESETIN_OUT input is usable as an external warm reset input source. [[br]]When 1 nRESETIN_OUT is not usable as warm reset input source (any input transitions on this pin or if the IO buffer is changed to disabled state will not cause a warm reset).
0x1404 CTRL_DDR_ADDRCTRL_IOCTRL
  [9:8] IO_CONFIG_SR_CLK rw — 2 bit to program clock IO Pads (CK/CK#) output Slew Rate
  [7:5] IO_CONFIG_I_CLK rw — 3 bit configuration input to program clock IO Pads (CK/CK#) output Impedance
  [4:3] IO_CONFIG_SR rw — 2 bit to program addr/cmd IO Pads output Slew Rate
  [2:0] IO_CONFIG_I rw — 3 bit configuration input to program addr/cmd IO Pad output Impedance
0x1408 CTRL_DDR_ADDRCTRL_WD0_IOCTRL rw
  [31:0] REG — WD0 - IO control [[br]]Bit mapping is as below:[[br]]31:30: Reserved[[br]]29: ddr_odt0[[br]]28: ddr_odt1[[br]]27: ddr_resetn[[br]]26: ddr_csn0[[br]]25: ddr_csn1[[br]]24: ddr_cke[[br]]23: ddr_ck[[br]]22: ddr_nck[[br]]21: ddr_casn[[br]]20: ddr_rasn[[br]]19: ddr_wen[[br]]18: ddr_ba0[[br]]17: ddr_ba1[[br]]16: ddr_ba2[[br]](15:0) : Addr(15:0)
0x140C CTRL_DDR_ADDRCTRL_WD1_IOCTRL rw
  [31:0] REG — WD1 - IO control [[br]]Bit mapping is as below:[[br]]31:30: Reserved[[br]]29: ddr_odt0[[br]]28: ddr_odt1[[br]]27: ddr_resetn[[br]]26: ddr_csn0[[br]]25: ddr_csn1[[br]]24: ddr_cke[[br]]23: ddr_ck[[br]]22: ddr_nck[[br]]21: ddr_casn[[br]]20: ddr_rasn[[br]]19: ddr_wen[[br]]18: ddr_ba0[[br]]17: ddr_ba1[[br]]16: ddr_ba2[[br]](15:0) : Addr(15:0)
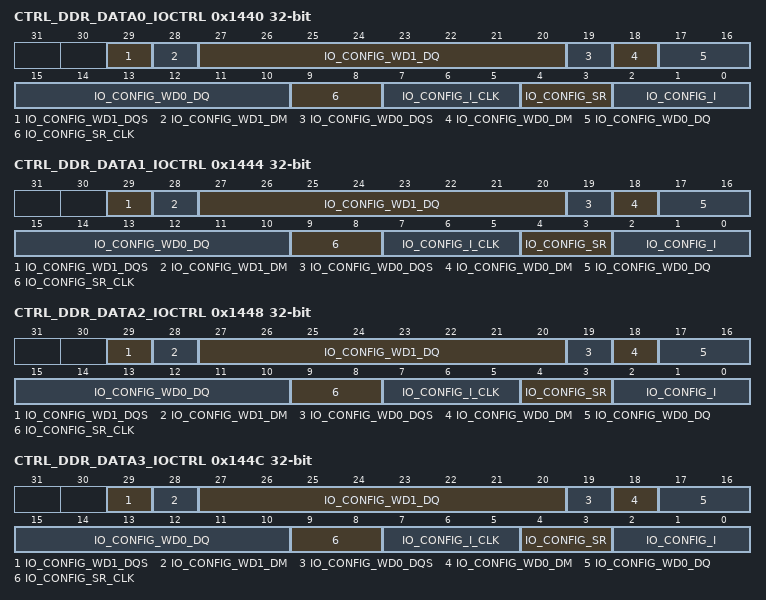
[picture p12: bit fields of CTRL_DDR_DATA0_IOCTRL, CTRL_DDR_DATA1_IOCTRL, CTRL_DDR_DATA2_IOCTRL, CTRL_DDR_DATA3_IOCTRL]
0x1440 CTRL_DDR_DATA0_IOCTRL
  [29] IO_CONFIG_WD1_DQS rw — This register bit controls WD1 of DQS0 [[br]]WD0 WD1[[br]]00 : Pullup/Pulldown disabled[[br]]01 : Weak pulldown enabled[[br]]10 : Weak pullup enabled[[br]]11 : Weak keeper enabled[[br]]Please refer to DDR IO buffer spec for details
  [28] IO_CONFIG_WD1_DM rw — This register bit controls WD1 of DM0 [[br]]WD0 WD1[[br]]00 : Pullup/Pulldown disabled[[br]]01 : Weak pulldown enabled[[br]]10 : Weak pullup enabled[[br]]11 : Weak keeper enabled[[br]]Please refer to DDR IO buffer spec for details
  [27:20] IO_CONFIG_WD1_DQ rw — This register controls WD1 of DDR data pins[[br]] Bit mapping is as below: [[br]]20: D(0) WD1 control[[br]]21: D(1) WD1 control[[br]]22: D(2) WD1 control[[br]]23: D(3) WD1 control[[br]]24: D(4) WD1 control[[br]]25: D(5) WD1 control[[br]]26: D(6) WD1 control[[br]]27: D(7) WD1 control[[br]]
  [19] IO_CONFIG_WD0_DQS rw — This register bit controls WD0 of DQS0 [[br]]WD0 WD1[[br]]00 : Pullup/Pulldown disabled[[br]]01 : Weak pulldown enabled[[br]]10 : Weak pullup enabled[[br]]11 : Weak keeper enabled[[br]]Please refer to DDR IO buffer spec for details
  [18] IO_CONFIG_WD0_DM rw — This register bit controls WD0 of DM0 [[br]]WD0 WD1[[br]]00 : Pullup/Pulldown disabled[[br]]01 : Weak pulldown enabled[[br]]10 : Weak pullup enabled[[br]]11 : Weak keeper enabled[[br]]Please refer to DDR IO buffer spec for details
  [17:10] IO_CONFIG_WD0_DQ rw — This register controls WD0 of DDR data pins[[br]] Bit mapping is as below: [[br]]10: D(0) WD0 control[[br]]11: D(1) WD0 control[[br]]12: D(2) WD0 control[[br]]13: D(3) WD0 control[[br]]14: D(4) WD0 control[[br]]15: D(5) WD0 control[[br]]16: D(6) WD0 control[[br]]17: D(7) WD0 control[[br]]
  [9:8] IO_CONFIG_SR_CLK rw — 2 bit to program clock IO Pads (DQS/DQS#) output Slew Rate
  [7:5] IO_CONFIG_I_CLK rw — 3 bit configuration input to program clock IO Pads (DQS/DQS#) output Impedance
  [4:3] IO_CONFIG_SR rw — 2 bit to program data IO Pads output Slew Rate for D(7 to 0)
  [2:0] IO_CONFIG_I rw — 3 bit configuration input to program data IO Pad output Impedance for D(7 to 0)
0x1444 CTRL_DDR_DATA1_IOCTRL
  [29] IO_CONFIG_WD1_DQS rw — This register bit controls WD1 of DQS1 [[br]]WD0 WD1[[br]]00 : Pullup/Pulldown disabled[[br]]01 : Weak pulldown enabled[[br]]10 : Weak pullup enabled[[br]]11 : Weak keeper enabled[[br]]Please refer to DDR IO buffer spec for details
  [28] IO_CONFIG_WD1_DM rw — This register bit controls WD1 of DM1 [[br]]WD0 WD1[[br]]00 : Pullup/Pulldown disabled[[br]]01 : Weak pulldown enabled[[br]]10 : Weak pullup enabled[[br]]11 : Weak keeper enabled[[br]]Please refer to DDR IO buffer spec for details
  [27:20] IO_CONFIG_WD1_DQ rw — This register controls WD1 of DDR data pins[[br]] Bit mapping is as below: [[br]]20: D(8) WD1 control[[br]]21: D(9) WD1 control[[br]]22: D(10) WD1 control[[br]]23: D(11) WD1 control[[br]]24: D(12) WD1 control[[br]]25: D(13) WD1 control[[br]]26: D(14) WD1 control[[br]]27: D(15) WD1 control[[br]]
  [19] IO_CONFIG_WD0_DQS rw — This register bit controls WD0 of DQS1 [[br]]WD0 WD1[[br]]00 : Pullup/Pulldown disabled[[br]]01 : Weak pulldown enabled[[br]]10 : Weak pullup enabled[[br]]11 : Weak keeper enabled[[br]]Please refer to DDR IO buffer spec for details
  [18] IO_CONFIG_WD0_DM rw — This register bit controls WD0 of DM1 [[br]]WD0 WD1[[br]]00 : Pullup/Pulldown disabled[[br]]01 : Weak pulldown enabled[[br]]10 : Weak pullup enabled[[br]]11 : Weak keeper enabled[[br]]Please refer to DDR IO buffer spec for details
  [17:10] IO_CONFIG_WD0_DQ rw — This register controls WD0 of DDR data pins[[br]] Bit mapping is as below: [[br]]10: D(8) WD0 control[[br]]11: D(9) WD0 control[[br]]12: D(10) WD0 control[[br]]13: D(11) WD0 control[[br]]14: D(12) WD0 control[[br]]15: D(13) WD0 control[[br]]16: D(14) WD0 control[[br]]17: D(15) WD0 control[[br]]
  [9:8] IO_CONFIG_SR_CLK rw — 2 bit to program clock IO Pads (DQS1/DQ1S#) output Slew Rate
  [7:5] IO_CONFIG_I_CLK rw — 3 bit configuration input to program clock IO Pads (DQS1/DQS1#) output Impedance
  [4:3] IO_CONFIG_SR rw — 2 bit to program data IO Pads output Slew Rate for D(15 to 8)
  [2:0] IO_CONFIG_I rw — 3 bit configuration input to program data IO Pad output Impedance for D(15 to 8)
0x1448 CTRL_DDR_DATA2_IOCTRL
  [29] IO_CONFIG_WD1_DQS rw — This register bit controls WD1 of DQS2 [[br]]WD0 WD1[[br]]00 : Pullup/Pulldown disabled[[br]]01 : Weak pulldown enabled[[br]]10 : Weak pullup enabled[[br]]11 : Weak keeper enabled[[br]]Please refer to DDR IO buffer spec for details
  [28] IO_CONFIG_WD1_DM rw — This register bit controls WD1 of DM2 [[br]]WD0 WD1[[br]]00 : Pullup/Pulldown disabled[[br]]01 : Weak pulldown enabled[[br]]10 : Weak pullup enabled[[br]]11 : Weak keeper enabled[[br]]Please refer to DDR IO buffer spec for details
  [27:20] IO_CONFIG_WD1_DQ rw — This register controls WD1 of DDR data pins[[br]] Bit mapping is as below: [[br]]20: D(16) WD1 control[[br]]21: D(17) WD1 control[[br]]22: D(18) WD1 control[[br]]23: D(19) WD1 control[[br]]24: D(20) WD1 control[[br]]25: D(21) WD1 control[[br]]26: D(22) WD1 control[[br]]27: D(23) WD1 control[[br]]
  [19] IO_CONFIG_WD0_DQS rw — This register bit controls WD0 of DQS2 [[br]]WD0 WD1[[br]]00 : Pullup/Pulldown disabled[[br]]01 : Weak pulldown enabled[[br]]10 : Weak pullup enabled[[br]]11 : Weak keeper enabled[[br]]Please refer to DDR IO buffer spec for details
  [18] IO_CONFIG_WD0_DM rw — This register bit controls WD0 of DM2 [[br]]WD0 WD1[[br]]00 : Pullup/Pulldown disabled[[br]]01 : Weak pulldown enabled[[br]]10 : Weak pullup enabled[[br]]11 : Weak keeper enabled[[br]]Please refer to DDR IO buffer spec for details
  [17:10] IO_CONFIG_WD0_DQ rw — This register controls WD0 of DDR data pins[[br]] Bit mapping is as below: [[br]]10: D(16) WD0 control[[br]]11: D(17) WD0 control[[br]]12: D(18) WD0 control[[br]]13: D(19) WD0 control[[br]]14: D(20) WD0 control[[br]]15: D(21) WD0 control[[br]]16: D(22) WD0 control[[br]]17: D(23) WD0 control[[br]]
  [9:8] IO_CONFIG_SR_CLK rw — 2 bit to program clock IO Pads (DQS2/DQS2#) output Slew Rate
  [7:5] IO_CONFIG_I_CLK rw — 3 bit configuration input to program clock IO Pads (DQS2/DQS2#) output Impedance
  [4:3] IO_CONFIG_SR rw — 2 bit to program data IO Pads output Slew Rate for D(16 to 23)
  [2:0] IO_CONFIG_I rw — 3 bit configuration input to program data IO Pad Impedance for D(23 to 16)
0x144C CTRL_DDR_DATA3_IOCTRL
  [29] IO_CONFIG_WD1_DQS rw — This register bit controls WD1 of DQS3 [[br]]WD0 WD1[[br]]00 : Pullup/Pulldown disabled[[br]]01 : Weak pulldown enabled[[br]]10 : Weak pullup enabled[[br]]11 : Weak keeper enabled[[br]]Please refer to DDR IO buffer spec for details
  [28] IO_CONFIG_WD1_DM rw — This register bit controls WD1 of DM3 [[br]]WD0 WD1[[br]]00 : Pullup/Pulldown disabled[[br]]01 : Weak pulldown enabled[[br]]10 : Weak pullup enabled[[br]]11 : Weak keeper enabled[[br]]Please refer to DDR IO buffer spec for details
  [27:20] IO_CONFIG_WD1_DQ rw — This register controls WD1 of DDR data pins[[br]] Bit mapping is as below: [[br]]20: D(24) WD1 control[[br]]21: D(25) WD1 control[[br]]22: D(26) WD1 control[[br]]23: D(27) WD1 control[[br]]24: D(28) WD1 control[[br]]25: D(29) WD1 control[[br]]26: D(30) WD1 control[[br]]27: D(31) WD1 control[[br]]
  [19] IO_CONFIG_WD0_DQS rw — This register bit controls WD0 of DQS3 [[br]]WD0 WD1[[br]]00 : Pullup/Pulldown disabled[[br]]01 : Weak pulldown enabled[[br]]10 : Weak pullup enabled[[br]]11 : Weak keeper enabled[[br]]Please refer to DDR IO buffer spec for details
  [18] IO_CONFIG_WD0_DM rw — This register bit controls WD0 of DM3 [[br]]WD0 WD1[[br]]00 : Pullup/Pulldown disabled[[br]]01 : Weak pulldown enabled[[br]]10 : Weak pullup enabled[[br]]11 : Weak keeper enabled[[br]]Please refer to DDR IO buffer spec for details
  [17:10] IO_CONFIG_WD0_DQ rw — This register controls WD0 of DDR data pins[[br]] Bit mapping is as below: [[br]]10: D(24) WD0 control[[br]]11: D(25) WD0 control[[br]]12: D(26) WD0 control[[br]]13: D(27) WD0 control[[br]]14: D(28) WD0 control[[br]]15: D(29) WD0 control[[br]]16: D(30) WD0 control[[br]]17: D(31) WD0 control[[br]]
  [9:8] IO_CONFIG_SR_CLK rw — 2 bit to program clock IO Pads (DQS3/DQS3#) output Slew Rate
  [7:5] IO_CONFIG_I_CLK rw — 3 bit configuration input to program clock IO Pads (DQS3/DQS3#) output Impedance
  [4:3] IO_CONFIG_SR rw — 2 bit to program data IO Pads output Slew Rate for D(31 to 24)
  [2:0] IO_CONFIG_I rw — 3 bit configuration input to program data IO Pad Impedance for D(31 to 24)
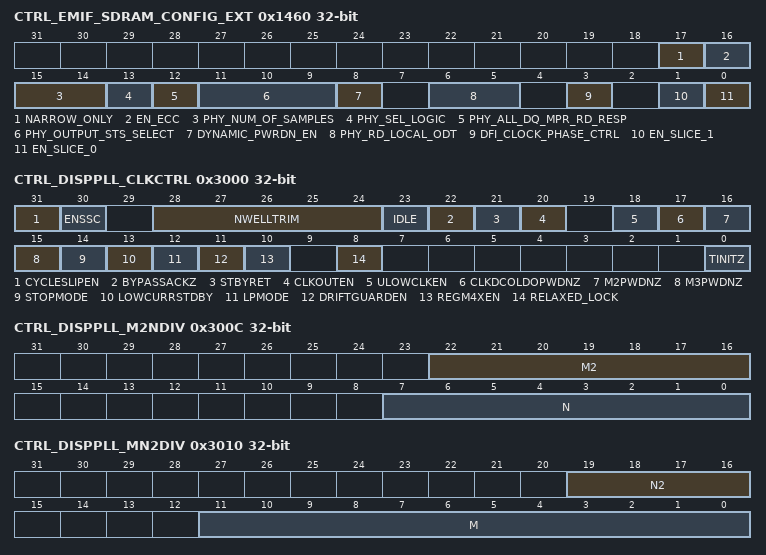
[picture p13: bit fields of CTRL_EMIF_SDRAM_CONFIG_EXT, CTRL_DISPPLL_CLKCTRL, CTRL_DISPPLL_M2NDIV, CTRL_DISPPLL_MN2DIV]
0x1460 CTRL_EMIF_SDRAM_CONFIG_EXT
  [17] NARROW_ONLY rw — Should be 1 if EMIF is operated in Narrow mode (16 bit only).
  [16] EN_ECC ro — ECC not supported - Reserved
  [15:14] PHY_NUM_OF_SAMPLES rw — Controls the number of samples used during read data eye training Should be 0x0 (4 samples) for incremental leveling and 0x3 (128 samples) for full leveling
  [13] PHY_SEL_LOGIC rw — Selects data read eye training algorithm Value 0(algorithm #1) is recommended
  [12] PHY_ALL_DQ_MPR_RD_RESP rw — Controls the number of DQ pins used during read data eye training Value 1 (all DQs used) is recommended if the memory provides a leveling response on all DQs value 0 (only one DQ) recommended if memory only provides a single DQ
  [11:9] PHY_OUTPUT_STS_SELECT rw — Use to select the status to be observed on the spare_out pins through EMIF_SDRAM_STATUS_EXT register [[br]]0: phy_reg_rdlvl_start_ratio(7 to 0)[[br]]1: phy_reg_rdlvl_start_ratio(15 to 8)[[br]]2: phy_reg_rdlvl_end_ratio(7 to 0)[[br]]3: phy_reg_rdlvl_end_ratio(15 to 8)
  [8] DYNAMIC_PWRDN_EN rw — Enables dynamic PWRDN control in the IOs to reduce power consumption
  [6:5] PHY_RD_LOCAL_ODT rw — DDR IOs termination control value during reads. [[br]]Used to control the termination resistance value. [[br]]ODT is enabled only during reads when termination is required. [[br]]Available values are described in the DDR IO spec.
  [3] DFI_CLOCK_PHASE_CTRL rw — DFI clock division phase control in EMIF4D5SS Recommended 0
  [1] EN_SLICE_1 rw — Enable CMD PHY1
  [0] EN_SLICE_0 rw — Enable CMD PHY0
0x1464 CTRL_EMIF_SDRAM_STS_EXT ro
  [31:0] REG — The bit mapping for this register, which connects to spareout of memss, is listed below:[[br]] Bits [31 to 24] - Slice3[[br]] Bits [23 to 16] - Slice2[[br]] Bits [15 to 8] - Slice1[[br]] Bits [7 to 0] - Slice0[[br]] When {EMIF_SDRAM_CFG_EXT[11:9]=0x0}, this status register reflects phy_reg_rdlvl_start_ratio[7:0] for the corresponding 8bit slice.[[br]] When {EMIF_SDRAM_CFG_EXT[11:9]= 0x1}, this status register reflects phy_reg_rdlvl_start_ratio[15:8] for the corresponding 8bit slice.[[br]] When {EMIF_SDRAM_CFG_EXT[11:9]= 0x2}, this status register reflects phy_reg_rdlvl_end_ratio[7:0] for the corresponding 8bit slice.[[br]] When {EMIF_SDRAM_CFG_EXT[11:9]= 0x3}, this status register reflects phy_reg_rdlvl_end_ratio[15:8] for the corresponding 8bit slice.
0x3000 CTRL_DISPPLL_CLKCTRL
  [31] CYCLESLIPEN rw — FailSafe enable to trigger re-calibration in case CycleSlip occurs between REFCLK and FBCLK.
  [30] ENSSC rw — Controls Clock Spreading [[br]]1: Enables clock spreading[[br]] [[br]]0: Disables clock spreading
  [28:24] NWELLTRIM rw — Trim values for the PLL
  [23] IDLE rw — Sets PLL to Idle mode. [[br]]When SYSRESET = 0 and TINITZ = 1 [[br]]0: PLL will go to Active and Locked[[br]] [[br]]1: PLL will go to Idle Bypass low power
  [22] BYPASSACKZ rw — Bypass status acknowledge signal.
  [21] STBYRET rw — Standby retention control [[br]]1: Prepares ADPLLLJ for retention by gating all the internal clocks[[br]] [[br]]0: Prepares ADPLLLJ for relock when out of retention by removing the gating on all internal clocks
  [20] CLKOUTEN rw — CLKOUT enable or disable [[br]]1: Synchronously enables CLKOUT[[br]] [[br]]0: Synchronously disables CLKOUT
  [18] ULOWCLKEN rw — Select CLKOUT source in bypass [[br]]0: When ADPLLLJ in bypass mode CLKOUT = CLKINP/(N2+1)[[br]] [[br]]1: When ADPLLLJ in bypass mode CLKOUT = CLKINPULOW
  [17] CLKDCOLDOPWDNZ rw — [[br]]0: Asynchronous power down for CLKDCOLDO o/p.
  [16] M2PWDNZ rw — [[br]]0: Asynchronous power down for M2 divider[[br]] [[br]]1: M2 divider is functional
  [15] M3PWDNZ rw — [[br]]0: Asynchronous power down for M3 divider[[br]] [[br]]1: M3 divider is functional
  [14] STOPMODE rw — When in Lossclk/Stbyret [[br]]0: Limp mode[[br]] [[br]]1: Stopmode
  [13] LOWCURRSTDBY rw — When in Lossclk/Stbyret/Idle [[br]]0: Fast relock[[br]] [[br]]1: Slow relock
  [12] LPMODE rw — Can be set to '1' in cases with CLKINP/(N+1) = 1MHz and CLKINP*M/(N+1) = 100MHz
  [11] DRIFTGUARDEN rw — When RECAL status flag is asserted '1' enables recalibration
  [10] REGM4XEN rw — Enable REGM*4 (Active High). [[br]]Can be set to '1' only for CLKOUT*M2 > 150MHz when LPMODE = '0' and CLKOUT*M2 > 60MHz when LPMODE = '1'. [[br]]This bit should not be changed on the fly in locked condition. [[br]]INITIALIZATION should follow change of this bit.
  [8] RELAXED_LOCK rw — [[br]]0: FREQLOCK asserted when DC frequency error 1%[[br]] [[br]]1: FREQLOCK asserted when DC frequency error 2%
  [0] TINITZ rw — PLL core soft reset
0x3004 CTRL_DISPPLL_TEN
  [0] TEN rw — M N. [[br]]SD and SELFREQDCO latch (active rise edge)
0x3008 CTRL_DISPPLL_TENIV
  [0] TENIV rw — M2 and N2 latch (active rise edge)
0x300C CTRL_DISPPLL_M2NDIV
  [22:16] M2 rw — Post-divider is REGM2
  [7:0] N rw — Pre-divider is REGN+1
0x3010 CTRL_DISPPLL_MN2DIV
  [19:16] N2 rw — Bypass divider is REGN2+1
  [11:0] M rw — Feedback multiplier is REGM
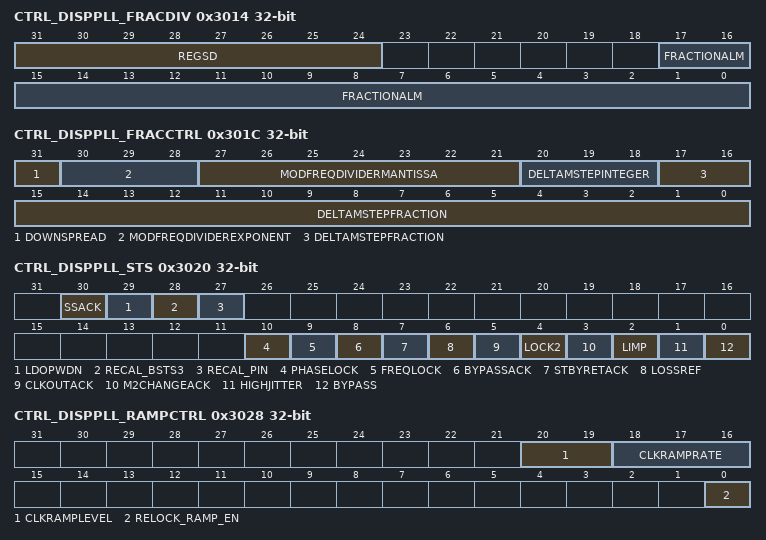
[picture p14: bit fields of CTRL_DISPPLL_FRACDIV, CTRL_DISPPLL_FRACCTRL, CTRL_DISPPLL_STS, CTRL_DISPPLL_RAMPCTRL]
0x3014 CTRL_DISPPLL_FRACDIV
  [31:24] REGSD ro — Sigma-Delta Divider
  [17:0] FRACTIONALM rw — Fractional part of the M divider.
0x3018 CTRL_DISPPLL_BWCTRL
  [2:1] BWCTRL rw — Change Loop Bandwidth
0x301C CTRL_DISPPLL_FRACCTRL rw
  [31] DOWNSPREAD — [[br]]1: Enables low frequency spread only[[br]] [[br]]0: Enables both side frequency spread about the programmed frequency
  [30:28] MODFREQDIVIDEREXPONENT — Exponent of the REFCLK divider to define the modulation frequency.
  [27:21] MODFREQDIVIDERMANTISSA — Mantissa of the REFCLK divider to define the modulation frequency
  [20:18] DELTAMSTEPINTEGER — Integer part of Frequency Spread control.
  [17:0] DELTAMSTEPFRACTION — The fraction part of Frequency Spread control
0x3020 CTRL_DISPPLL_STS ro
  [30] SSACK — [[br]]1: Spread-spectrum Clocking is enabled on output clocks (default)[[br]] [[br]]0: Spread-spectrum Clocking is disabled on output clocks
  [29] LDOPWDN — [[br]]1: Indicates ADPLLLJ internal LDO is power down. [[br]]VDDLDOOUT will be un-defined in this condition. [[br]](default)
  [28] RECAL_BSTS3 — Recalibration status flag. [[br]]1: ADPLLLJ requires recalibration)
  [27] RECAL_PIN — Recalibration status flag. [[br]]1: ADPLLLJ requires recalibration)
  [10] PHASELOCK — Status on PHASELOCK output pin
  [9] FREQLOCK — Status on FREQLOCK output pin
  [8] BYPASSACK — Status of BYPASSACK output pin (default:1)
  [7] STBYRETACK — [[br]]1: Indicates to SOC that all internal clocks in ADPLLLJ are gated and it is ready for retention. [[br]]0: Indicates to SOC that all internal clocks in ADPLLLJ are active and it is starting the relock process.
  [6] LOSSREF — Reference input loss
  [5] CLKOUTACK — 1/[[br]]0: Indicates enable/disable condition of CLKOUT (default:1)
  [4] LOCK2 — ADPLL internal loop lock status
  [3] M2CHANGEACK — acknowledge for M2 change
  [2] LIMP — [[br]]1: In LIMP mode[[br]] [[br]]0: In Stop Mode
  [1] HIGHJITTER — [[br]]1: Indicates jitter. [[br]]After PHASELOCK is asserted high the HIGHJITTER flag is asserted high if phase error between REFCLK and FBCLK 24%.
  [0] BYPASS — Bypass status signal. [[br]]1: CLKOUT in bypass
0x3024 CTRL_DISPPLL_M3DIV
  [4:0] M3 rw — Post Divider Reg M3
0x3028 CTRL_DISPPLL_RAMPCTRL
  [20:19] CLKRAMPLEVEL rw — Controls the ramp sequence. [[br]]00: No ramping[[br]] [[br]]01: Bypass clk /Fout/8 / Fout/4 / Fout/2 / Fout[[br]] [[br]]10: Bypass clk / Fout/4 / Fout/2 / Fout/1.5 /Fout[[br]] [[br]]11: Reserved
  [18:16] CLKRAMPRATE rw — Controls the time spent on each ramp step. [[br]]000: 2 REFCLKs[[br]] [[br]]001: 4 REFCLKs[[br]] [[br]]010: 8 REFCLKs[[br]] [[br]]011: 16 REFCLKs[[br]] [[br]]100: 32 REFCLKs[[br]] [[br]]101: 64 REFCLKs[[br]] [[br]]110: 128 REFCLKs[[br]] [[br]]111: 512 REFCLKs
  [0] RELOCK_RAMP_EN rw
